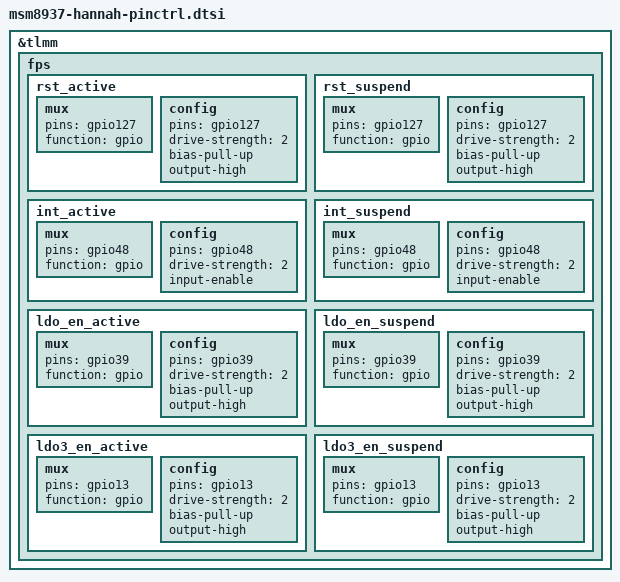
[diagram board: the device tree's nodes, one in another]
/* Copyright (c) 2016, Motorola Mobility Inc. All rights reserved.
 *
 * This program is free software; you can redistribute it and/or modify
 * it under the terms of the GNU General Public License version 2 and
 * only version 2 as published by the Free Software Foundation.
 *
 * This program is distributed in the hope that it will be useful,
 * but WITHOUT ANY WARRANTY; without even the implied warranty of
 * MERCHANTABILITY or FITNESS FOR A PARTICULAR PURPOSE.  See the
 * GNU General Public License for more details.
 */

&tlmm{
	/delete-node/ fps;
	fps: fps {
		rst_active: rst_active {
			/* RESET */
			mux {
				pins = "gpio127";
				function = "gpio";
			};

			config {
				pins = "gpio127";
				drive-strength = <2>; /* 2 MA */
				bias-pull-up; /* pull up */
				output-high;
			};
		};

		rst_suspend: rst_suspend{
			/* RESET */
			mux {
				pins = "gpio127";
				function = "gpio";
			};

			config {
				pins = "gpio127";
				drive-strength = <2>; /* 2 MA */
				bias-pull-up; /* pull up */
				output-high;
			};
		};

		int_active: int_active {
			/* INTERRUPT */
			mux {
				pins = "gpio48";
				function = "gpio";
			};

			config {
				pins = "gpio48";
				drive-strength = <2>; /* 2 MA */
				input-enable;
			};
		};

		int_suspend: int_suspend{
			/* INTERRUPT */
			mux {
				pins = "gpio48";
				function = "gpio";
			};

			config {
				pins = "gpio48";
				drive-strength = <2>; /* 2 MA */
				input-enable;
			};
		};

		ldo_en_active: ldo_en_active {
			/* LDO_EN */
			mux {
				pins = "gpio39";
				function = "gpio";
			};

			config {
				pins = "gpio39";
				drive-strength = <2>; /* 2 MA */
				bias-pull-up; /* pull up */
				output-high;
			};
		};

		ldo_en_suspend: ldo_en_suspend{
			/* LDO_EN */
			mux {
				pins = "gpio39";
				function = "gpio";
			};

			config {
				pins = "gpio39";
				drive-strength = <2>; /* 2 MA */
				bias-pull-up; /* pull up */
				output-high;
			};
		};

		ldo3_en_active: ldo3_en_active {
			/* LDO3_EN */
			mux {
				pins = "gpio13";
				function = "gpio";
			};

			config {
				pins = "gpio13";
				drive-strength = <2>; /* 2 MA */
				bias-pull-up; /* pull up */
				output-high;
			};
		};

		ldo3_en_suspend: ldo3_en_suspend{
			/* LDO3_EN */
			mux {
				pins = "gpio13";
				function = "gpio";
			};

			config {
				pins = "gpio13";
				drive-strength = <2>; /* 2 MA */
				bias-pull-up; /* pull up */
				output-high;
			};
		};
	};
};
